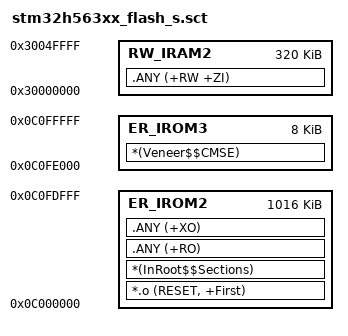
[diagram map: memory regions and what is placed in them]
; *************************************************************
; *** Scatter-Loading Description File generated by uVision ***
; *************************************************************

LR_IROM2 0x0C000000 0x000FE000  {    ; load region size_region               Memory is divided. Actual start is 0x0C000000 and actual length is 2048K
  ER_IROM2 0x0C000000 0x000FE000  {  ; load address = execution address
   *.o (RESET, +First)
   *(InRoot$$Sections)
   .ANY (+RO)
   .ANY (+XO)
  }
  RW_IRAM2 0x30000000 0x00050000  {  ; RW data                               Memory is divided. Actual start is 0x30000000 and actual length is 768K
   .ANY (+RW +ZI)
  }
}

LR_IROM3 0x0C0FE000 0x00002000  {    ; load region size_region               Non-Secure Call-able region
  ER_IROM3 0x0C0FE000 0x00002000  {  ; load address = execution address
   *(Veneer$$CMSE)                   ; check with partition.h
  }
}
